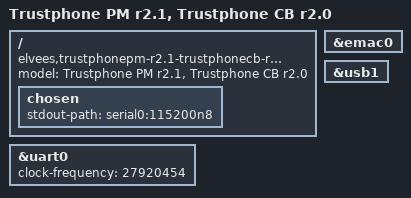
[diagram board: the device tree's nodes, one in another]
// SPDX-License-Identifier: GPL-2.0+
/*
 * Copyright 2022 RnD Center "ELVEES", JSC
 */

/dts-v1/;

#include "mcom03-trustphonepm-r2.1.dtsi"

/ {
	model = "Trustphone PM r2.1, Trustphone CB r2.0";
	compatible = "elvees,trustphonepm-r2.1-trustphonecb-r2.0",
		     "elvees,trustphonepm-trustphonecb",
		     "elvees,trustphonecb-r2.0",
		     "elvees,trustphonecb",
		     "elvees,trustphonepm-r2.1",
		     "elvees,trustphonepm",
		     "elvees,mcom03";

	chosen {
		stdout-path = "serial0:115200n8";
	};
};

&uart0 {
	status = "okay";
	clock-frequency = <27920454>;
};

&emac0 {
	status = "okay";
};

/* Connected to USB hub */
&usb1 {
	status = "okay";
};
